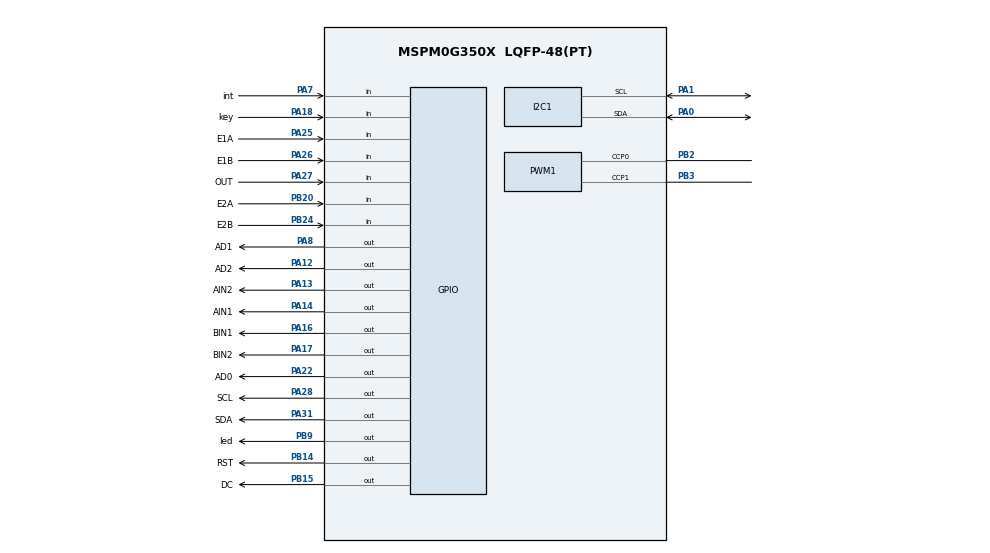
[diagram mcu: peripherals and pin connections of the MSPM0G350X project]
/**
 *
 * @cliArgs --device "MSPM0G350X" --part "Default" --package "LQFP-48(PT)" --product "mspm0_sdk@2.10.00.04"
 * @versions {"tool":"1.28.0+4696"}
 */

/**
 * Import the modules used in this configuration.
 */
const GPIO   = scripting.addModule("/ti/driverlib/GPIO", {}, false);
const GPIO1  = GPIO.addInstance();
const GPIO2  = GPIO.addInstance();
const GPIO3  = GPIO.addInstance();
const GPIO4  = GPIO.addInstance();
const GPIO5  = GPIO.addInstance();
const GPIO6  = GPIO.addInstance();
const GPIO7  = GPIO.addInstance();
const GPIO8  = GPIO.addInstance();
const GPIO9  = GPIO.addInstance();
const GPIO10 = GPIO.addInstance();
const GPIO11 = GPIO.addInstance();
const GPIO12 = GPIO.addInstance();
const I2C    = scripting.addModule("/ti/driverlib/I2C", {}, false);
const I2C1   = I2C.addInstance();
const PWM    = scripting.addModule("/ti/driverlib/PWM", {}, false);
const PWM1   = PWM.addInstance();
const SYSCTL = scripting.addModule("/ti/driverlib/SYSCTL");
const TIMER  = scripting.addModule("/ti/driverlib/TIMER", {}, false);
const TIMER1 = TIMER.addInstance();

/**
 * Write custom configuration values to the imported modules.
 */
GPIO1.$name                         = "AIN";
GPIO1.associatedPins.create(2);
GPIO1.associatedPins[0].$name       = "AIN1";
GPIO1.associatedPins[0].pin.$assign = "PA14";
GPIO1.associatedPins[1].$name       = "AIN2";
GPIO1.associatedPins[1].pin.$assign = "PA13";

const Board = scripting.addModule("/ti/driverlib/Board", {}, false);

GPIO2.$name                         = "BIN";
GPIO2.associatedPins.create(2);
GPIO2.associatedPins[0].$name       = "BIN1";
GPIO2.associatedPins[0].pin.$assign = "PA16";
GPIO2.associatedPins[1].$name       = "BIN2";
GPIO2.associatedPins[1].pin.$assign = "PA17";

GPIO3.$name                         = "ENCODERA";
GPIO3.associatedPins.create(2);
GPIO3.associatedPins[0].$name       = "E1A";
GPIO3.associatedPins[0].direction   = "INPUT";
GPIO3.associatedPins[0].interruptEn = true;
GPIO3.associatedPins[0].polarity    = "RISE_FALL";
GPIO3.associatedPins[0].pin.$assign = "PA25";
GPIO3.associatedPins[1].$name       = "E1B";
GPIO3.associatedPins[1].direction   = "INPUT";
GPIO3.associatedPins[1].interruptEn = true;
GPIO3.associatedPins[1].polarity    = "RISE_FALL";
GPIO3.associatedPins[1].pin.$assign = "PA26";

GPIO4.$name                         = "ENCODERB";
GPIO4.associatedPins.create(2);
GPIO4.associatedPins[0].$name       = "E2A";
GPIO4.associatedPins[0].direction   = "INPUT";
GPIO4.associatedPins[0].interruptEn = true;
GPIO4.associatedPins[0].polarity    = "RISE_FALL";
GPIO4.associatedPins[0].pin.$assign = "PB20";
GPIO4.associatedPins[1].$name       = "E2B";
GPIO4.associatedPins[1].direction   = "INPUT";
GPIO4.associatedPins[1].interruptEn = true;
GPIO4.associatedPins[1].polarity    = "RISE_FALL";
GPIO4.associatedPins[1].pin.$assign = "PB24";

GPIO5.$name                         = "KEY";
GPIO5.associatedPins[0].$name       = "key";
GPIO5.associatedPins[0].direction   = "INPUT";
GPIO5.associatedPins[0].pin.$assign = "PA18";

GPIO6.$name                          = "LED";
GPIO6.associatedPins[0].$name        = "led";
GPIO6.associatedPins[0].initialValue = "SET";
GPIO6.associatedPins[0].pin.$assign  = "PB9";

GPIO7.$name                         = "LINE_SENSOR";
GPIO7.associatedPins.create(4);
GPIO7.associatedPins[0].$name       = "AD0";
GPIO7.associatedPins[0].pin.$assign = "PA22";
GPIO7.associatedPins[1].$name       = "AD1";
GPIO7.associatedPins[1].pin.$assign = "PA8";
GPIO7.associatedPins[2].$name       = "AD2";
GPIO7.associatedPins[2].pin.$assign = "PA12";
GPIO7.associatedPins[3].$name       = "OUT";
GPIO7.associatedPins[3].direction   = "INPUT";
GPIO7.associatedPins[3].pin.$assign = "PA27";

GPIO8.$name                         = "IMU_INT";
GPIO8.associatedPins[0].$name       = "int";
GPIO8.associatedPins[0].direction   = "INPUT";
GPIO8.associatedPins[0].interruptEn = true;
GPIO8.associatedPins[0].polarity    = "RISE";
GPIO8.associatedPins[0].pin.$assign = "PA7";

GPIO9.$name                          = "OLED_RST";
GPIO9.associatedPins[0].$name        = "RST";
GPIO9.associatedPins[0].initialValue = "SET";
GPIO9.associatedPins[0].pin.$assign  = "PB14";

GPIO10.$name                          = "OLED_DC";
GPIO10.associatedPins[0].$name        = "DC";
GPIO10.associatedPins[0].initialValue = "SET";
GPIO10.associatedPins[0].pin.$assign  = "PB15";

GPIO11.$name                          = "OLED_SCL";
GPIO11.associatedPins[0].$name        = "SCL";
GPIO11.associatedPins[0].initialValue = "SET";
GPIO11.associatedPins[0].pin.$assign  = "PA28";

GPIO12.$name                          = "OLED_SDA";
GPIO12.associatedPins[0].$name        = "SDA";
GPIO12.associatedPins[0].initialValue = "SET";
GPIO12.associatedPins[0].pin.$assign  = "PA31";

I2C1.$name                             = "I2C_IMU";
I2C1.basicEnableController             = true;
I2C1.basicControllerStandardBusSpeed   = "Fast";
I2C1.peripheral.$assign                = "I2C0";
I2C1.peripheral.sdaPin.$assign         = "PA0";
I2C1.peripheral.sclPin.$assign         = "PA1";
I2C1.sdaPinConfig.hideOutputInversion  = scripting.forceWrite(false);
I2C1.sdaPinConfig.onlyInternalResistor = scripting.forceWrite(false);
I2C1.sdaPinConfig.passedPeripheralType = scripting.forceWrite("Digital");
I2C1.sdaPinConfig.$name                = "ti_driverlib_gpio_GPIOPinGeneric2";
I2C1.sclPinConfig.hideOutputInversion  = scripting.forceWrite(false);
I2C1.sclPinConfig.onlyInternalResistor = scripting.forceWrite(false);
I2C1.sclPinConfig.passedPeripheralType = scripting.forceWrite("Digital");
I2C1.sclPinConfig.$name                = "ti_driverlib_gpio_GPIOPinGeneric3";

PWM1.$name                      = "PWM_0";
PWM1.timerCount                 = 8000;
PWM1.pwmMode                    = "EDGE_ALIGN_UP";
PWM1.peripheral.$assign         = "TIMG6";
PWM1.peripheral.ccp0Pin.$assign = "PB2";
PWM1.peripheral.ccp1Pin.$assign = "PB3";
PWM1.PWM_CHANNEL_0.$name        = "ti_driverlib_pwm_PWMTimerCC0";
PWM1.PWM_CHANNEL_1.$name        = "ti_driverlib_pwm_PWMTimerCC1";
PWM1.ccp0PinConfig.$name        = "ti_driverlib_gpio_GPIOPinGeneric0";
PWM1.ccp1PinConfig.$name        = "ti_driverlib_gpio_GPIOPinGeneric1";

SYSCTL.forceDefaultClkConfig = true;

TIMER1.$name              = "TIMER_0";
TIMER1.timerMode          = "PERIODIC";
TIMER1.timerPeriod        = "5 ms";
TIMER1.interrupts         = ["ZERO"];
TIMER1.timerClkPrescale   = 4;
TIMER1.peripheral.$assign = "TIMG0";

const ProjectConfig              = scripting.addModule("/ti/project_config/ProjectConfig", {}, false);
ProjectConfig.migrationCondition = true;

/**
 * Pinmux solution for unlocked pins/peripherals. This ensures that minor changes to the automatic solver in a future
 * version of the tool will not impact the pinmux you originally saw.  These lines can be completely deleted in order to
 * re-solve from scratch.
 */
Board.peripheral.$suggestSolution          = "DEBUGSS";
Board.peripheral.swclkPin.$suggestSolution = "PA20";
Board.peripheral.swdioPin.$suggestSolution = "PA19";
SYSCTL.peripheral.$suggestSolution         = "SYSCTL";
